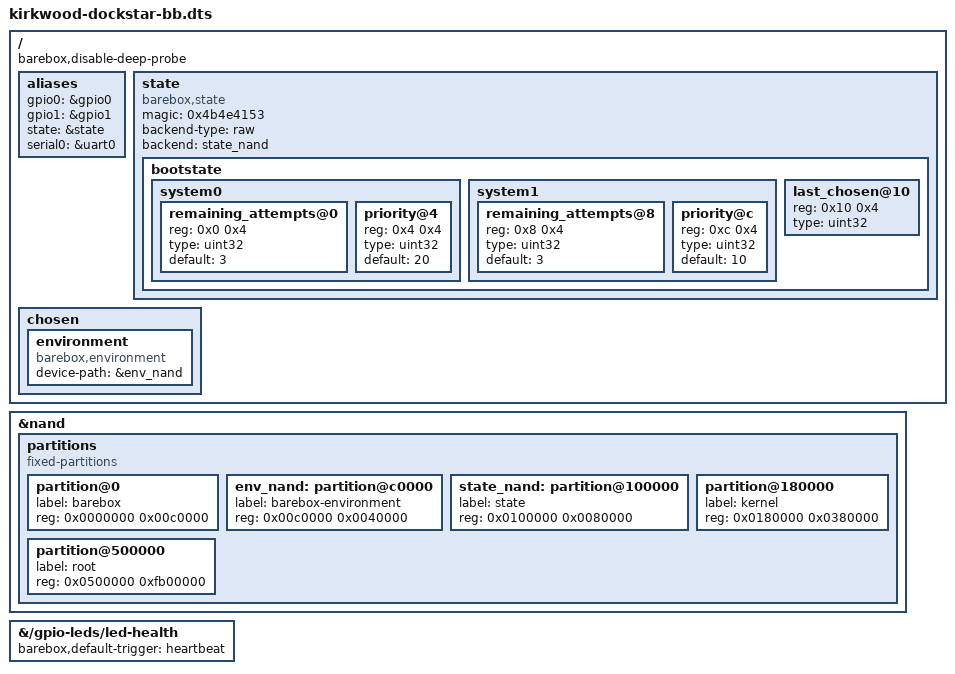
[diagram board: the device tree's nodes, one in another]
// SPDX-License-Identifier: GPL-2.0-or-later
/*
 * barebox specific additions for the Seagate FreeAgent DockStar
 *
 * NAND layout (256 MiB, 128 KiB erase blocks, 2 KiB pages):
 *
 *   0x00000000 - 0x000bffff  barebox              (768 KiB, kwbimage v0)
 *   0x000c0000 - 0x000fffff  barebox-environment  (256 KiB, 1 spare block)
 *   0x00100000 - 0x0017ffff  state                (512 KiB, barebox state)
 *   0x00180000 - 0x004fffff  kernel               (3.5 MiB, raw zImage)
 *   0x00500000 - 0x0fffffff  root                 (UBI)
 *
 * The first 1 MiB is the same area the U-Boot partition used to occupy,
 * so kernel and root stay where the stock/OpenWrt/Debian layouts have them.
 */

#include "arm/marvell/kirkwood-dockstar.dts"

/ {
	barebox,disable-deep-probe;

	/*
	 * Fixed GPIO numbering as in Linux and the Marvell documentation:
	 * bank 0 is GPIO 0-31, bank 1 is GPIO 32-49.
	 */
	aliases {
		gpio0 = &gpio0;
		gpio1 = &gpio1;
		/* the state driver names the state after its alias */
		state = &state;
		/* barebox adds console=ttyS0,115200n8 only for aliased UARTs */
		serial0 = &uart0;
	};

	state: state {
		magic = <0x4b4e4153>;	/* "KNAS" */
		compatible = "barebox,state";
		backend-type = "raw";
		backend = <&state_nand>;
		/* NAND needs erase before write: circular storage type */
		#address-cells = <1>;
		#size-cells = <1>;

		bootstate {
			#address-cells = <1>;
			#size-cells = <1>;

			/* names must match RAUC's bootname= and barebox bootchooser targets */
			system0 {
				#address-cells = <1>;
				#size-cells = <1>;

				remaining_attempts@0 {
					reg = <0x0 0x4>;
					type = "uint32";
					default = <3>;
				};
				priority@4 {
					reg = <0x4 0x4>;
					type = "uint32";
					default = <20>;
				};
			};

			system1 {
				#address-cells = <1>;
				#size-cells = <1>;

				remaining_attempts@8 {
					reg = <0x8 0x4>;
					type = "uint32";
					default = <3>;
				};
				priority@c {
					reg = <0xc 0x4>;
					type = "uint32";
					default = <10>;
				};
			};

			last_chosen@10 {
				reg = <0x10 0x4>;
				type = "uint32";
			};
		};
	};

	chosen {
		environment {
			compatible = "barebox,environment";
			device-path = &env_nand;
		};
	};
};

&nand {
	/delete-node/ partition@0;
	/delete-node/ partition@100000;
	/delete-node/ partition@500000;

	partitions {
		compatible = "fixed-partitions";
		#address-cells = <1>;
		#size-cells = <1>;

		partition@0 {
			label = "barebox";
			reg = <0x0000000 0x00c0000>;
		};

		env_nand: partition@c0000 {
			label = "barebox-environment";
			reg = <0x00c0000 0x0040000>;
		};

		state_nand: partition@100000 {
			label = "state";
			reg = <0x0100000 0x0080000>;
		};

		partition@180000 {
			label = "kernel";
			reg = <0x0180000 0x0380000>;
		};

		partition@500000 {
			label = "root";
			reg = <0x0500000 0xfb00000>;
		};
	};
};

&{/gpio-leds/led-health} {
	barebox,default-trigger = "heartbeat";
};
